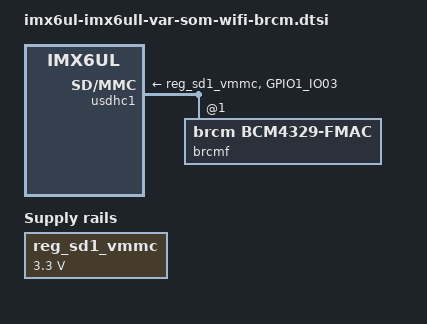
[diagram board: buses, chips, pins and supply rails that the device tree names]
// SPDX-License-Identifier: GPL-2.0+
/*
 * Copyright (C) 2026 Variscite Ltd. - https://www.variscite.com
 */

/ {
	reg_sd1_vmmc: regulator-sd1-vmmc {
		compatible = "regulator-fixed";
		regulator-name = "VSD_3V3";
		regulator-min-microvolt = <3300000>;
		regulator-max-microvolt = <3300000>;
	};
};

&tsc {
	status = "disabled";
};

&usdhc1 {
	#address-cells = <1>;
	#size-cells = <0>;
	pinctrl-names = "default", "state_100mhz", "state_200mhz";
	pinctrl-0 = <&pinctrl_usdhc1>, <&pinctrl_32k_clk>, <&pinctrl_wifi>;
	pinctrl-1 = <&pinctrl_usdhc1_100mhz>, <&pinctrl_32k_clk>, <&pinctrl_wifi>;
	pinctrl-2 = <&pinctrl_usdhc1_200mhz>, <&pinctrl_32k_clk>, <&pinctrl_wifi>;
	keep-power-in-suspend;
	vmmc-supply = <&reg_sd1_vmmc>;
	status = "okay";

	brcmf: wifi@1 {
		compatible = "brcm,bcm4329-fmac";
		reg = <1>;
	};
};

&iomuxc {
	pinctrl_32k_clk: 32k-clk-grp {
		fsl,pins = <
			MX6UL_PAD_GPIO1_IO03__OSC32K_32K_OUT	0x03029
		>;
	};
};
